# NUC121AE_v1 register map
File version: 1.0
NUC121AE_v1 SVD file
Registers are 32-bit, read-write, reset 0x0 unless marked. A register's access mark holds for its fields unless they carry their own. Offsets are from the block's base; lines under a group give offsets from that group; [hi:lo] are bit positions; {n}, {i} and the like mark numbered series; 'fields as' and 'values as' point back to an identical list; <NAME> marks a mode.

## Memory map
0x40004000 WDT blocks up to offset 0x1000 — WDT Register Map
0x40004100 WWDT size 0x10 — WWDT Register Map
0x40010000 TMR01 blocks up to offset 0x3C — TIMER Register Map
0x40011000 TMR23 blocks up to offset 0x3C — TIMER Register Map
0x40020000 I2C0 blocks up to offset 0x50 — I2C Register Map
0x40030000 SPI blocks up to offset 0x6C — SPI Register Map
0x40040000 BPWM0 blocks up to offset 0x334 — BPWM Register Map
0x40044000 PWM0 blocks up to offset 0x334 — PWM Register Map
0x40050000 UART0 size 0x4C — UART Register Map
0x40060000 USBD blocks up to offset 0x580 — USBD Register Map
0x40070000 UUART0 blocks up to offset 0x68 — UUART Register Map
0x40070000 USPI0 blocks up to offset 0x68 — USPI Register Map
0x40070000 UI2C0 blocks up to offset 0x90 — UI2C Register Map
0x400E0000 ADC blocks up to offset 0x104 — ADC Register Map
0x40120000 I2C1 blocks up to offset 0x50 — I2C Register Map
0x40140000 BPWM1 blocks up to offset 0x334 — BPWM Register Map
0x40144000 PWM1 blocks up to offset 0x334 — PWM Register Map
0x50000000 SYS blocks up to offset 0x118 — SYS Register Map
0x50000200 CLK blocks up to offset 0x80 — CLK Register Map
0x50000300 INT size 0x8C — INT Register Map
0x50004000 GPIO blocks up to offset 0x360 — GPIO Register Map
0x50008000 PDMA blocks up to offset 0x488 — PDMA Register Map
0x5000C000 FMC blocks up to offset 0x44 — FMC Register Map
0xE000E000 SCS blocks up to offset 0xD24 — SYST_NVIC_SCS Register Map

## WWDT — WWDT Register Map
Base 0x40004100
0x00 WWDT_RLDCNT wo — WWDT Reload Counter Register
  [31:0] RLDCNT — WWDT Reload Counter Register. Writing 0x00005AA5 to this register will reload the WWDT counter value to 0x3F. Note1: User can only execute the reload WWDT counter value command when current CNTDAT (WWDT_CNT[5:0]) is between 1 and CMPDAT (WWDT_CTL[21:16]). If user writes 0x00005AA5 in WWDT_RLDCNT register when current CNTDAT is larger than CMPDAT, WWDT reset system event will be generated immediately. Note2: Execute WWDT counter reload always needs (WWDT_CLK *3) period to reload CNTDAT to 0x3F and internal prescale counter will be reset also.
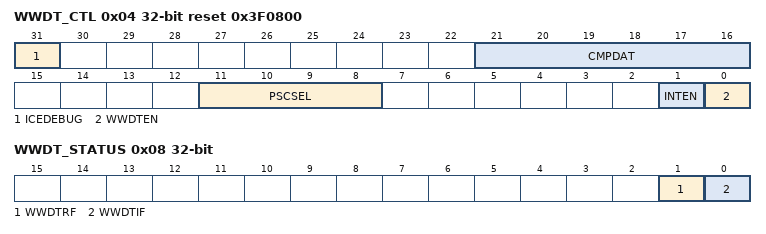
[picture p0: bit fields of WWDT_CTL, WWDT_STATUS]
0x04 WWDT_CTL reset 0x3F0800 — WWDT Control Register
  [31] ICEDEBUG — ICE Debug Mode Acknowledge Disable Control. WWDT down counter will keep going no matter CPU is held by ICE or not.
    0=ICE debug mode acknowledgement effects WWDT counting; 1=ICE debug mode acknowledgement Disabled
  [21:16] CMPDAT — WWDT Window Compare Value. Set this field to adjust the valid reload window interval when WWDTIF (WWDT_STATUS[0]) is generated. Note: User can only write WWDT_RLDCNT register to reload WWDT counter value when current CNTDAT (WWDT_CNT[5:0]) is between 1 and CMPDAT. If user writes 0x00005AA5 in WWDT_RLDCNT register when current CNTDAT is larger than CMPDAT, WWDT reset system event will be generated immediately.
  [11:8] PSCSEL — WWDT Counter Prescale Period Selection
    0=Pre-scale is 1; Max time-out period is 1 * 64 * WWDT_CLK; 1=Pre-scale is 2; Max time-out period is 2 * 64 * WWDT_CLK; 2=Pre-scale is 4; Max time-out period is 4 * 64 * WWDT_CLK; 3=Pre-scale is 8; Max time-out period is 8 * 64 * WWDT_CLK; 4=Pre-scale is 16; Max time-out period is 16 * 64 * WWDT_CLK; 5=Pre-scale is 32; Max time-out period is 32 * 64 * WWDT_CLK; 6=Pre-scale is 64; Max time-out period is 64 * 64 * WWDT_CLK; 7=Pre-scale is 128; Max time-out period is 128 * 64 * WWDT_CLK; 8=Pre-scale is 192; Max time-out period is 192 * 64 * WWDT_CLK; 9=Pre-scale is 256; Max time-out period is 256 * 64 * WWDT_CLK; 10=Pre-scale is 384; Max time-out period is 384 * 64 * WWDT_CLK; 11=Pre-scale is 512; Max time-out period is 512 * 64 * WWDT_CLK; 12=Pre-scale is 768; Max time-out period is 768 * 64 * WWDT_CLK; 13=Pre-scale is 1024; Max time-out period is 1024 * 64 * WWDT_CLK; 14=Pre-scale is 1536; Max time-out period is 1536 * 64 * WWDT_CLK; 15=Pre-scale is 2048; Max time-out period is 2048 * 64 * WWDT_CLK
  [1] INTEN — WWDT Interrupt Enable Control Bit. If this bit is enabled, when WWDTIF (WWDT_STATUS[0]) is set to 1, the WWDT counter compare match interrupt signal is generated and inform to CPU.
    0=WWDT counter compare match interrupt Disabled; 1=WWDT counter compare match interrupt Enabled
  [0] WWDTEN — WWDT Enable Control Bit. Set this bit to enable WWDT counter counting.
    0=WWDT counter is stopped; 1=WWDT counter is starting counting
0x08 WWDT_STATUS
  [1] WWDTRF — WWDT Timer-out Reset Flag. If this bit is set to 1, it indicates that system has been reset by WWDT counter time-out reset system event. Note: This bit is cleared by writing 1 to it.
    0=WWDT time-out reset system event did not occur; 1=WWDT time-out reset system event occurred
  [0] WWDTIF — WWDT Compare Match Interrupt Flag. This bit indicates that current CNTDAT (WWDT_CNT[5:0]) matches the CMPDAT (WWDT_CTL[21:16]). Note: This bit is cleared by writing 1 to it.
    0=No effect; 1=WWDT counter value matches CMPDAT
0x0C WWDT_CNT ro reset 0x3F — WWDT Counter Value Register
  [5:0] CNTDAT — WWDT Counter Value. CNTDAT will be updated continuously
